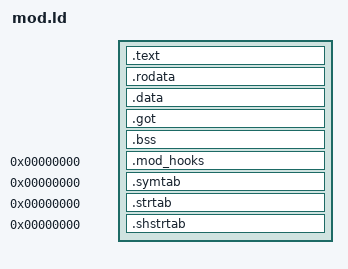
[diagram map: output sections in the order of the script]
/* A mod's link: generated by recomp --mod-api; do not edit.
 *
 * The image goes at MOD_ORIGIN (mods/build.sh --origin; the mod region's
 * base by default) and must end before the region's guard word and stack.
 * .mod_hooks is not loaded: the runtime reads it from the ELF. Each game
 * function is a symbol at its address, and mod_call_original is the
 * runtime's. */

ENTRY(mod_entry_none)
mod_entry_none = 0;

mod_call_original = 0x0dfffff0;
ram_00100000 = 0x00100000;
ram_00100020 = 0x00100020;
ram_00100040 = 0x00100040;

mod_origin = DEFINED(MOD_ORIGIN) ? MOD_ORIGIN : 0x0e000000;

SECTIONS {
	. = mod_origin;
	.text : { *(.text .text.*) }
	.rodata : { *(.rodata .rodata.*) }
	.data : { *(.data .data.* .sdata .sdata.*) }
	.got : { *(.got) }
	.bss : { *(.bss .bss.* .sbss .sbss.* COMMON) }
	mod_end = .;
	.mod_hooks 0 (INFO) : { KEEP(*(.mod_hooks)) }
	.symtab 0 : { *(.symtab) }
	.strtab 0 : { *(.strtab) }
	.shstrtab 0 : { *(.shstrtab) }
	/DISCARD/ : { *(.eh_frame*) *(.MIPS.*) *(.reginfo) *(.pdr) *(.comment) *(.gnu.attributes) *(.mdebug.*) }
}

/* build.sh links with --orphan-handling=error: every loaded section is one
 * of the above, so mod_end is the image's end. */
ASSERT(mod_origin >= 0x0e000000 && mod_origin < 0x0effbff0, "mod: the origin is outside the mod region")
ASSERT(mod_origin % 16 == 0, "mod: the origin is not 16-byte aligned")
ASSERT(mod_end <= 0x0effbff0, "mod: the image runs past the mod region (its stack and guard)")
